# S32K324_M7 register map
Vendor: NXP Semiconductors; File version: 1.1
CPU: CM7 r0p1, little endian, MPU, FPU, VTOR, 4 interrupt priority bits
Registers are 32-bit, read-write, reset 0x0 unless marked. A register's access mark holds for its fields unless they carry their own. Offsets are from the block's base; [hi:lo] are bit positions; lines under a group give offsets from that group; {n}, {i} and the like mark numbered series; 'fields as' and 'values as' point back to an identical list.

## CMU_0 — CMU_FC
Base 0x402BC000
Same registers: CMU_3 0x402BC060, CMU_4 0x402BC080, CMU_5 0x402BC0A0
0x00 GCR — Global Configuration Register
  [0] FCE — Frequency Check Enable
    0=bfv_gcr_fce_0 (Stops frequency checking); 1=bfv_gcr_fce_1 (Starts frequency checking)
0x04 RCCR — Reference Count Configuration Register
  [15:0] REF_CNT — Reference clock count
0x08 HTCR reset 0xFFFFFF — High Threshold Configuration Register
  [23:0] HFREF — High frequency reference threshold
0x0C LTCR — Low Threshold Configuration Register
  [23:0] LFREF — Low Frequency Reference Threshold
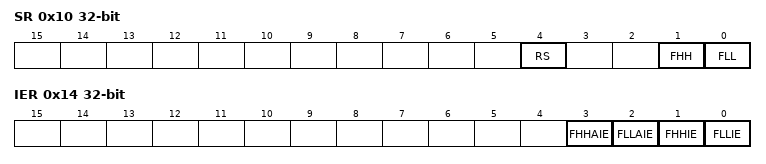
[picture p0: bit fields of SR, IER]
0x10 SR — Status Register
  [4] RS ro — Run Status
    0=bfv_sr_rs_0 (Frequency check stopped); 1=bfv_sr_rs_1 (Frequency check running)
  [1] FHH write-1-clears — Frequency higher than high frequency reference threshold event status
    0=bfv_sr_fhh_0 (No FHH event); 1=bfv_sr_fhh_1 (FHH event occurred)
  [0] FLL write-1-clears — Frequency lower than low frequency reference threshold event status
    0=bfv_sr_fll_0 (No FLL event); 1=bfv_sr_fll_1 (FLL event occurred)
0x14 IER — Interrupt Enable Register
  [3] FHHAIE — Frequency Higher than High Frequency Reference Threshold Asynchronous Interrupt Enable
    0=bfv_ier_fhhaie_0 (Asynchronous FHH event interrupt disabled); 1=bfv_ier_fhhaie_1 (Asynchronous FHH event interrupt enabled)
  [2] FLLAIE — Frequency Lower than Low Frequency Reference Threshold Asynchronous Interrupt Enable
    0=bfv_ier_fllaie_0 (Asynchronous FLL event interrupt disabled); 1=bfv_ier_fllaie_1 (Asynchronous FLL event interrupt enabled)
  [1] FHHIE — Frequency Higher than High Frequency Reference Threshold Synchronous Interrupt Enable
    0=bfv_ier_fhhie_0 (Synchronous FHH event interrupt disabled); 1=bfv_ier_fhhie_1 (Synchronous FHH event interrupt enabled)
  [0] FLLIE — Frequency Lower than Low Frequency Reference Threshold Synchronous Interrupt Enable
    0=bfv_ier_fllie_0 (Synchronous FLL event interrupt disabled); 1=bfv_ier_fllie_1 (Synchronous FLL event interrupt enabled)

## CMU_1 — CMU_FM
Base 0x402BC020
Same registers: CMU_2 0x402BC040
0x00 GCR — Global Configuration Register
  [0] FME — Frequency Meter Enable
    0=bfv_fme_0 (Stops frequency metering); 1=bfv_fme_1 (Starts frequency metering)
0x04 RCCR — Reference Count Configuration Register
  [15:0] REF_CNT — Reference Clock Count
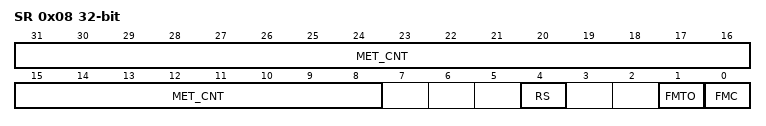
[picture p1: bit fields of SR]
0x08 SR — Status Register
  [31:8] MET_CNT ro — Meter Clock Count
  [4] RS ro — Run Status
    0=bfv_rs_0 (Frequency meter stopped); 1=bfv_rs_1 (Frequency meter running)
  [1] FMTO write-1-clears — Frequency Meter Time Out
  [0] FMC write-1-clears — Frequency Meter Operation Complete
0x0C IER — Interrupt Enable Register
  [0] FMCIE — Frequency Meter Complete Interrupt Enable
    0=bfv_fmcie_0 (Frequency Meter complete interrupt is disabled); 1=bfv_fmcie_1 (Frequency Meter complete interrupt is enabled)

## TSPC
Base 0x402C4000
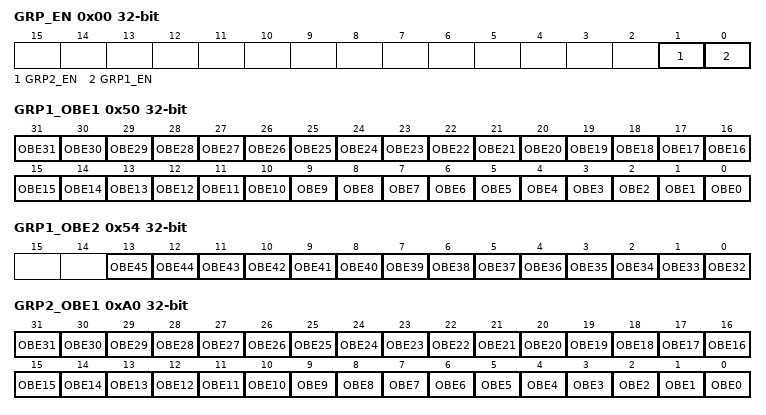
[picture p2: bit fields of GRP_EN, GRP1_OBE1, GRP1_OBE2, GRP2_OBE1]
0x00 GRP_EN — Group Enable
  [1] GRP2_EN — Enable for GRP2_OBEn Register
    0=GRP2_value0 (Disable); 1=GRP2_value1 (Enable)
  [0] GRP1_EN — Enable for GRP1_OBEn Register
    0=GRP1_value0 (Disable); 1=GRP1_value1 (Enable)
0x50 GRP1_OBE1 — Group OBE
  [n] OBE{n} (n=0..31) — Output Buffer Enable
    0=OBE{n}_value0 (OBE pad does not transition if any OBE in group transitions from high to low. The OBE pad value is unaltered at the output.); 1=OBE{n}_value1 (OBE pad transitions from high to low if any OBE in group transitions from high to low.)
0x54 GRP1_OBE2 — Group OBE
  [n-32] OBE{n} (n=32..45) — Output Buffer Enable
    values as GRP1_OBE1.OBE0
0xA0 GRP2_OBE1 — Group OBE
  fields as GRP1_OBE1
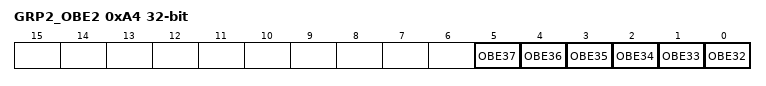
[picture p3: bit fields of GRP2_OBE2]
0xA4 GRP2_OBE2 — Group OBE
  [n-32] OBE{n} (n=32..37) — Output Buffer Enable
    values as GRP1_OBE1.OBE0
